# cmem7 register map
File version: 1.0
Registers are 32-bit, read-write, reset 0x0 unless marked. A register's access mark holds for its fields unless they carry their own. Offsets are from the block's base; [hi:lo] are bit positions; {n}, {i} and the like mark numbered series; 'fields as' and 'values as' point back to an identical list.

## NOR_FLASH
Base 0x40800000
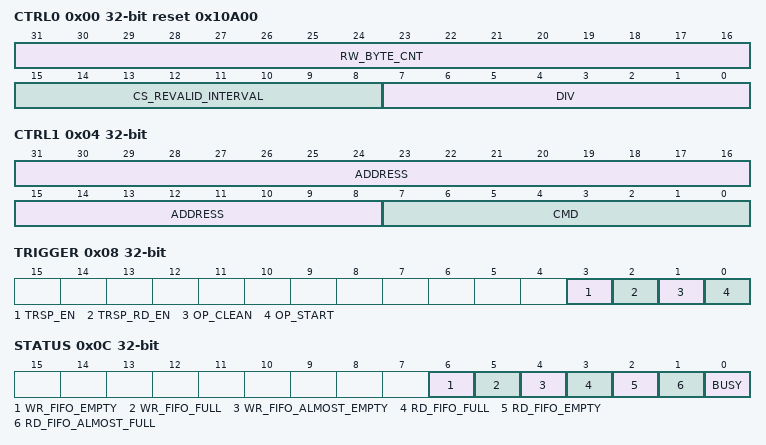
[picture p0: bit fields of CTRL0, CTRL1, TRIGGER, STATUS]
0x00 CTRL0 reset 0x10A00 — control Register 0
  [31:16] RW_BYTE_CNT — RW byte count (eliminate CMD, ADDRESS, DUMMY in normal state, contains all in transparent state. 0 is unlimited
  [15:8] CS_REVALID_INTERVAL — interval from CS invalid to valid, number of half cycle of SCK
  [7:0] DIV — frequency division register, fsck = fclk_io / (DIV + 1) / 2
0x04 CTRL1 — control Register 1
  [31:8] ADDRESS — RW address
  [7:0] CMD — operated command
0x08 TRIGGER
  [3] TRSP_EN — enable transparent operation
  [2] TRSP_RD_EN — if a read operation after transparent operation
  [1] OP_CLEAN — operation clean, stop current opration and clean FIFO
  [0] OP_START wo — operation start.
0x0C STATUS ro
  [6] WR_FIFO_EMPTY — write FIFO is empty
  [5] WR_FIFO_FULL — write FIFO is full
  [4] WR_FIFO_ALMOST_EMPTY — write FIFO is almost empty
  [3] RD_FIFO_FULL — read FIFO is full
  [2] RD_FIFO_EMPTY — read FIFO is empty
  [1] RD_FIFO_ALMOST_FULL — read FIFO is almost full
  [0] BUSY — reading or writting
0x10 DATA — data register. lower bits are significant in read and higher bits are significant in writting
0x14 BYPASS — bypass Register, is used for JTAG connecting FLASH directly
  [0] EN — enable bypass

## EFUSE
Base 0x41008000
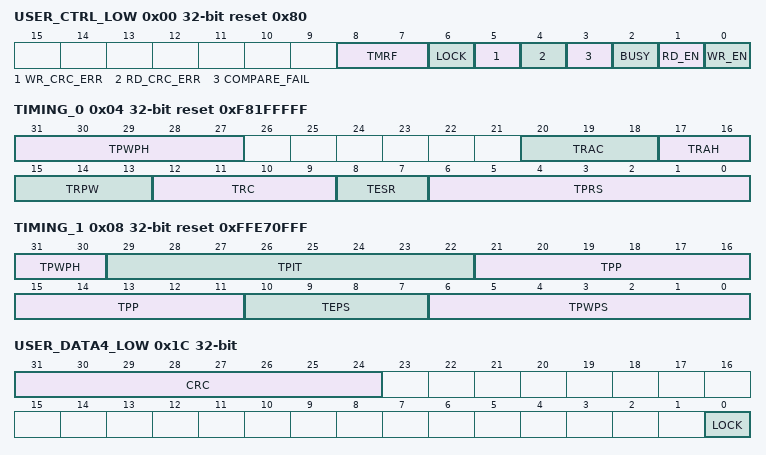
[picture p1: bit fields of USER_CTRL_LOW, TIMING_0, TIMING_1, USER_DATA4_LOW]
0x00 USER_CTRL_LOW reset 0x80 — low user region control
  [8:7] TMRF — Reference resistor select, 1200ohm is recommended
    0=REF_R_3000 (Reference resistor is 3000ohm); 1=REF_R_1200 (Reference resistor is 1200ohm); 2=REF_R_750 (Reference resistor is 750ohm)
  [6] LOCK ro — user region in EFUSE is locked, EFUSE can't be burn
  [5] WR_CRC_ERR ro — CRC error in writting
  [4] RD_CRC_ERR ro — CRC error in reading
  [3] COMPARE_FAIL — data read isn't consist with EFUSE
  [2] BUSY ro — reading or writting
  [1] RD_EN read-clears — read enable. 1 : write data into EFUSE. clear 0 after read
  [0] WR_EN read-clears — write enable. 1 : write data into EFUSE. clear 0 after read
0x04 TIMING_0 reset 0xF81FFFFF
  [31:27] TPWPH — TPWPH[6:2]
  [20:18] TRAC
  [17:16] TRAH
  [15:13] TRPW
  [12:9] TRC
  [8:7] TESR
  [6:0] TPRS
0x08 TIMING_1 reset 0xFFE70FFF
  [31:30] TPWPH — TPWPS[1:0]
  [29:22] TPIT
  [21:11] TPP
  [10:7] TEPS
  [6:0] TPWPS
{0xC+4i} USER_DATA{i}_LOW (i=0..3) — user data [{32i+31}:{32i}]
0x1C USER_DATA4_LOW — crc and lock bit
  [31:24] CRC
  [0] LOCK — write protection if true
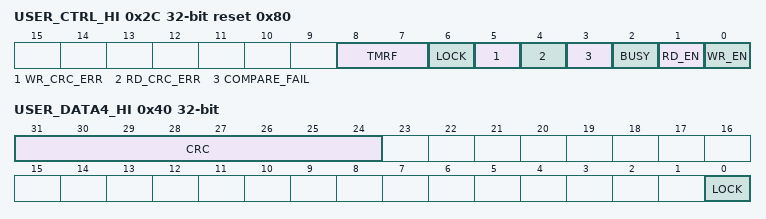
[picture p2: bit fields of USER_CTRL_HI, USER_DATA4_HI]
0x2C USER_CTRL_HI reset 0x80 — high user region control
  fields as USER_CTRL_LOW
{0x30+4i} USER_DATA{i}_HI (i=0..3) — user data [{32i+159}:{32i+128}]
0x40 USER_DATA4_HI — crc and lock bit
  [31:24] CRC
  [0] LOCK — write protection if true

## AES
Base 0x41600000
0x00 FIFO — data FIFO to be decoded
0x04 FIFO_CLEAR wo — clear data FIFO
  [0] CLEAR — clear after write 1 and write 0

## PDLOCK — PLL DLL LOCK
Base 0x41007000
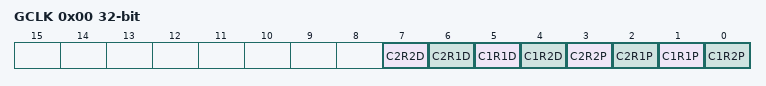
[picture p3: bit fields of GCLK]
0x00 GCLK ro
  [7] C2R2D — gclk_c2r2_dll_lock
  [6] C2R1D — gclk_c2r1_dll_lock
  [5] C1R1D — gclk_c1r1_dll_lock
  [4] C1R2D — gclk_c1r2_dll_lock
  [3] C2R2P — gclk_c2r2_pll_lock
  [2] C2R1P — gclk_c2r1_pll_lock
  [1] C1R1P — gclk_c1r1_pll_lock
  [0] C1R2P — gclk_c1r2_pll_lock

## PDPROT — PLL DLL PROTECT
Base 0x41007C00
0x00 LOCK wo
  [0] EN — Enable the PLL DLL Lock to Protect it

## CFG_CTRL
Base 0x41700000
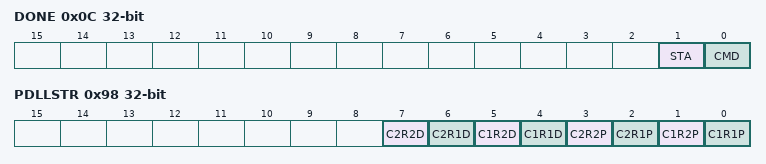
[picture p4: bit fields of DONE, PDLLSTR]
0x0C DONE — DONE CFG
  [1] STA — 1= all chain config process over, chip is in user mode
  [0] CMD — Write 1 indicate all chain data write over
0x98 PDLLSTR — PLL DLL RESET
  [7] C2R2D — C2r2_rstdll_n, low active
  [6] C2R1D — C2r1_rstdll_n, low active
  [5] C1R2D — C1r2_rstdll_n, low active
  [4] C1R1D — C1r1_rstdll_n, low active
  [3] C2R2P — C2r2_rstpll_n, low active
  [2] C2R1P — C2r1_rstpll_n, low active
  [1] C1R2P — C1r2_rstpll_n, low active
  [0] C1R1P — C1r1_rstpll_n, low active

## SOFT_RESET — SUB SOFT RESET
Base 0x41007400
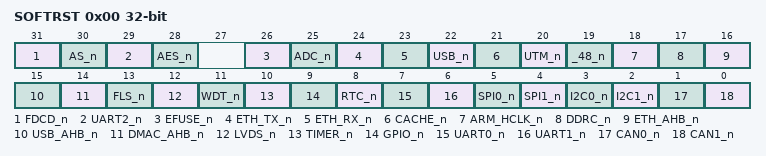
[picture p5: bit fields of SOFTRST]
0x00 SOFTRST
  [31] FDCD_n — soft_rst_fdcd_n
  [30] AS_n — soft_rst_as_n
  [29] UART2_n — soft_rst_uart2_n
  [28] AES_n — soft_rst_aes_n
  [26] EFUSE_n — soft_rst_efuse_n
  [25] ADC_n — soft_rst_adc_n
  [24] ETH_TX_n — soft_rst_eth_tx_i_n
  [23] ETH_RX_n — soft_rst_eth_rx_i_n
  [22] USB_n — soft_rst_cache_n
  [21] CACHE_n — soft_rst_cache_n
  [20] UTM_n — soft_rst_utmi_n
  [19] _48_n — soft_rst_48_n
  [18] ARM_HCLK_n — soft_rst_arm_HCLK_n
  [17] DDRC_n — soft_rst_ddrc_n
  [16] ETH_AHB_n — soft_rst_eth_ahb_n
  [15] USB_AHB_n — soft_rst_usb_ahb_n
  [14] DMAC_AHB_n — soft_rst_dmac_ahb_n
  [13] FLS_n — soft_rst_fls_n
  [12] LVDS_n — soft_rst_lvds_n
  [11] WDT_n — soft_rst_wdt_n
  [10] TIMER_n — soft_rst_timer_n
  [9] GPIO_n — soft_rst_gpio_n
  [8] RTC_n — soft_rst_rtc_n
  [7] UART0_n — soft_rst_uart0_n
  [6] UART1_n — soft_rst_uart1_n
  [5] SPI0_n — soft_rst_spi0_n
  [4] SPI1_n — soft_rst_spi1_n
  [3] I2C0_n — soft_rst_i2c0_n
  [2] I2C1_n — soft_rst_i2c1_n
  [1] CAN0_n — soft_rst_can0_n
  [0] CAN1_n — soft_rst_can1_n
